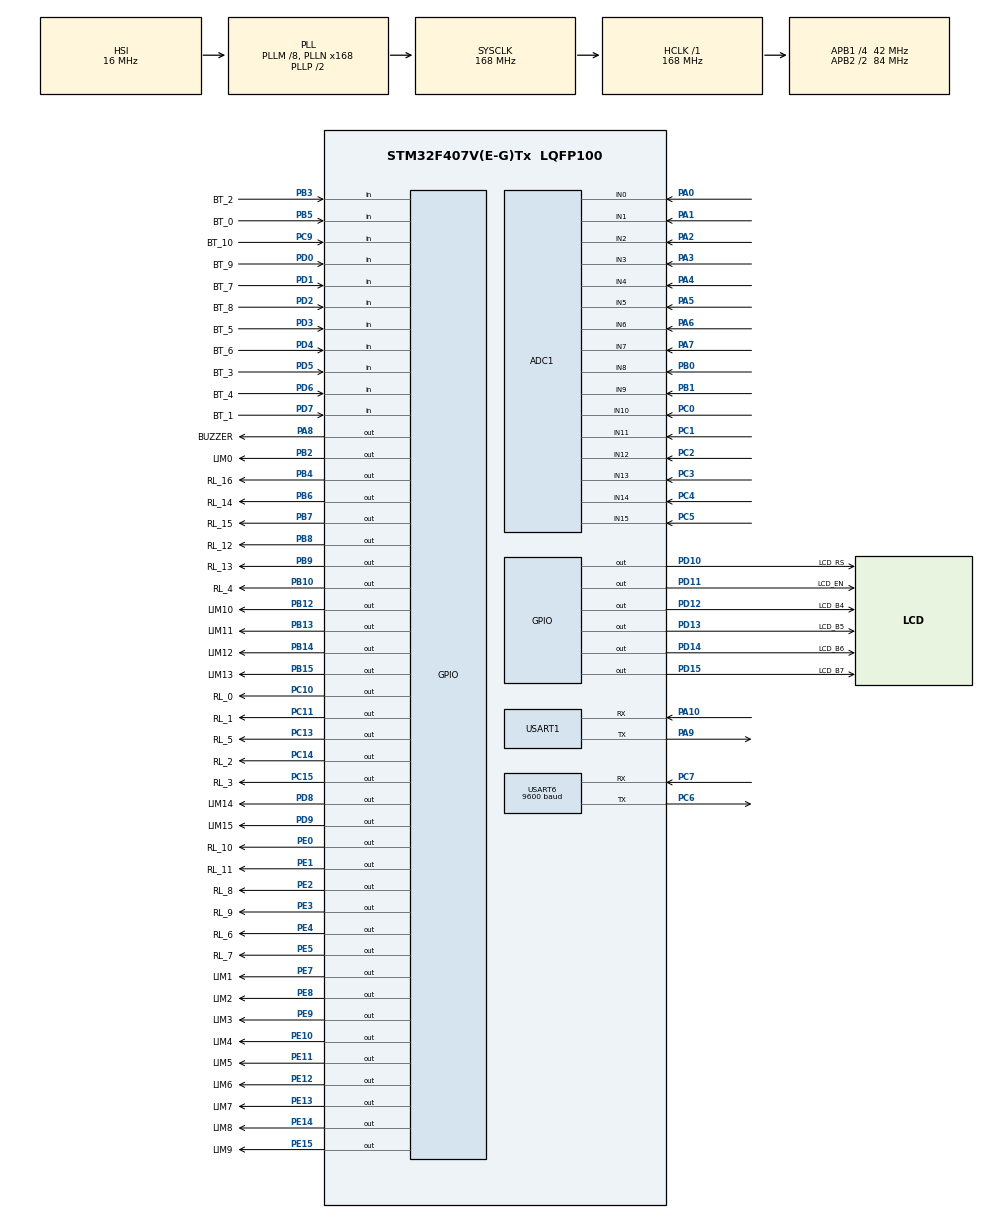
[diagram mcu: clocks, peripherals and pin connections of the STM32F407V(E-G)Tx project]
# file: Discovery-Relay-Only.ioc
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ADC1.Channel-0\#ChannelRegularConversion=ADC_CHANNEL_10
ADC1.Channel-1\#ChannelRegularConversion=ADC_CHANNEL_11
ADC1.Channel-10\#ChannelRegularConversion=ADC_CHANNEL_6
ADC1.Channel-11\#ChannelRegularConversion=ADC_CHANNEL_7
ADC1.Channel-12\#ChannelRegularConversion=ADC_CHANNEL_14
ADC1.Channel-13\#ChannelRegularConversion=ADC_CHANNEL_15
ADC1.Channel-14\#ChannelRegularConversion=ADC_CHANNEL_8
ADC1.Channel-15\#ChannelRegularConversion=ADC_CHANNEL_9
ADC1.Channel-2\#ChannelRegularConversion=ADC_CHANNEL_12
ADC1.Channel-3\#ChannelRegularConversion=ADC_CHANNEL_13
ADC1.Channel-4\#ChannelRegularConversion=ADC_CHANNEL_0
ADC1.Channel-5\#ChannelRegularConversion=ADC_CHANNEL_1
ADC1.Channel-6\#ChannelRegularConversion=ADC_CHANNEL_2
ADC1.Channel-7\#ChannelRegularConversion=ADC_CHANNEL_3
ADC1.Channel-8\#ChannelRegularConversion=ADC_CHANNEL_4
ADC1.Channel-9\#ChannelRegularConversion=ADC_CHANNEL_5
ADC1.ContinuousConvMode=ENABLE
ADC1.DMAContinuousRequests=ENABLE
ADC1.NbrOfConversion=16
ADC1.NbrOfConversionFlag=1
ADC1.Rank-0\#ChannelRegularConversion=1
ADC1.Rank-1\#ChannelRegularConversion=2
ADC1.Rank-10\#ChannelRegularConversion=11
ADC1.Rank-11\#ChannelRegularConversion=12
ADC1.Rank-12\#ChannelRegularConversion=13
ADC1.Rank-13\#ChannelRegularConversion=14
ADC1.Rank-14\#ChannelRegularConversion=15
ADC1.Rank-15\#ChannelRegularConversion=16
ADC1.Rank-2\#ChannelRegularConversion=3
ADC1.Rank-3\#ChannelRegularConversion=4
ADC1.Rank-4\#ChannelRegularConversion=5
ADC1.Rank-5\#ChannelRegularConversion=6
ADC1.Rank-6\#ChannelRegularConversion=7
ADC1.Rank-7\#ChannelRegularConversion=8
ADC1.Rank-8\#ChannelRegularConversion=9
ADC1.Rank-9\#ChannelRegularConversion=10
ADC1.SamplingTime-0\#ChannelRegularConversion=ADC_SAMPLETIME_480CYCLES
ADC1.SamplingTime-1\#ChannelRegularConversion=ADC_SAMPLETIME_480CYCLES
ADC1.SamplingTime-10\#ChannelRegularConversion=ADC_SAMPLETIME_480CYCLES
ADC1.SamplingTime-11\#ChannelRegularConversion=ADC_SAMPLETIME_480CYCLES
ADC1.SamplingTime-12\#ChannelRegularConversion=ADC_SAMPLETIME_480CYCLES
ADC1.SamplingTime-13\#ChannelRegularConversion=ADC_SAMPLETIME_480CYCLES
ADC1.SamplingTime-14\#ChannelRegularConversion=ADC_SAMPLETIME_480CYCLES
ADC1.SamplingTime-15\#ChannelRegularConversion=ADC_SAMPLETIME_480CYCLES
ADC1.SamplingTime-2\#ChannelRegularConversion=ADC_SAMPLETIME_480CYCLES
ADC1.SamplingTime-3\#ChannelRegularConversion=ADC_SAMPLETIME_480CYCLES
ADC1.SamplingTime-4\#ChannelRegularConversion=ADC_SAMPLETIME_480CYCLES
ADC1.SamplingTime-5\#ChannelRegularConversion=ADC_SAMPLETIME_480CYCLES
ADC1.SamplingTime-6\#ChannelRegularConversion=ADC_SAMPLETIME_480CYCLES
ADC1.SamplingTime-7\#ChannelRegularConversion=ADC_SAMPLETIME_480CYCLES
ADC1.SamplingTime-8\#ChannelRegularConversion=ADC_SAMPLETIME_480CYCLES
ADC1.SamplingTime-9\#ChannelRegularConversion=ADC_SAMPLETIME_480CYCLES
ADC1.ScanConvMode=ENABLE
ADC1.master=1
Dma.ADC1.0.Direction=DMA_PERIPH_TO_MEMORY
Dma.ADC1.0.FIFOMode=DMA_FIFOMODE_DISABLE
Dma.ADC1.0.Instance=DMA2_Stream0
Dma.ADC1.0.MemDataAlignment=DMA_MDATAALIGN_WORD
Dma.ADC1.0.MemInc=DMA_MINC_ENABLE
Dma.ADC1.0.Mode=DMA_CIRCULAR
Dma.ADC1.0.PeriphDataAlignment=DMA_PDATAALIGN_WORD
Dma.ADC1.0.PeriphInc=DMA_PINC_DISABLE
Dma.ADC1.0.Priority=DMA_PRIORITY_LOW
Dma.Request0=ADC1
Dma.Request1=USART1_RX
Dma.USART1_RX.1.Direction=DMA_PERIPH_TO_MEMORY
Dma.USART1_RX.1.FIFOMode=DMA_FIFOMODE_DISABLE
Dma.USART1_RX.1.Instance=DMA2_Stream2
Dma.USART1_RX.1.MemDataAlignment=DMA_MDATAALIGN_BYTE
Dma.USART1_RX.1.MemInc=DMA_MINC_ENABLE
Dma.USART1_RX.1.Mode=DMA_NORMAL
Dma.USART1_RX.1.PeriphDataAlignment=DMA_PDATAALIGN_BYTE
Dma.USART1_RX.1.PeriphInc=DMA_PINC_DISABLE
Dma.USART1_RX.1.Priority=DMA_PRIORITY_LOW
Mcu.Family=STM32F4
Mcu.Name=STM32F407V(E-G)Tx
Mcu.Package=LQFP100
NVIC.DMA2_Stream0_IRQn=true\:0\:0\:false\:false\:true\:false\:true\:true
NVIC.DMA2_Stream2_IRQn=true\:0\:0\:false\:false\:true\:false\:true\:true
NVIC.PriorityGroup=NVIC_PRIORITYGROUP_4
NVIC.TIM6_DAC_IRQn=true\:0\:0\:false\:false\:true\:true\:true\:true
NVIC.USART1_IRQn=true\:0\:0\:false\:false\:true\:true\:true\:true
NVIC.USART6_IRQn=true\:0\:0\:false\:false\:true\:true\:true\:true
PA0-WKUP.Signal=ADCx_IN0
PA1.Signal=ADCx_IN1
PA10.Mode=Asynchronous
PA10.Signal=USART1_RX
PA13.Mode=Serial_Wire
PA13.Signal=SYS_JTMS-SWDIO
PA14.Mode=Serial_Wire
PA14.Signal=SYS_JTCK-SWCLK
PA2.Signal=ADCx_IN2
PA3.Signal=ADCx_IN3
PA4.Signal=ADCx_IN4
PA5.Signal=ADCx_IN5
PA6.Signal=ADCx_IN6
PA7.Signal=ADCx_IN7
PA8.GPIO_Label=BUZZER
PA8.Signal=GPIO_Output
PA9.Mode=Asynchronous
PA9.Signal=USART1_TX
PB0.Signal=ADCx_IN8
PB1.Signal=ADCx_IN9
PB10.GPIO_Label=RL_4
PB10.Signal=GPIO_Output
PB12.GPIO_Label=LIM10
PB12.Signal=GPIO_Output
PB13.GPIO_Label=LIM11
PB13.Signal=GPIO_Output
PB14.GPIO_Label=LIM12
PB14.Signal=GPIO_Output
PB15.GPIO_Label=LIM13
PB15.Signal=GPIO_Output
PB2.GPIO_Label=LIM0
PB2.Signal=GPIO_Output
PB3.GPIO_Label=BT_2
PB3.GPIO_PuPd=GPIO_PULLUP
PB3.Signal=GPIO_Input
PB4.GPIO_Label=RL_16
PB4.Signal=GPIO_Output
PB5.GPIO_Label=BT_0
PB5.GPIO_PuPd=GPIO_PULLUP
PB5.Signal=GPIO_Input
PB6.GPIO_Label=RL_14
PB6.Signal=GPIO_Output
PB7.GPIO_Label=RL_15
PB7.Signal=GPIO_Output
PB8.GPIO_Label=RL_12
PB8.Signal=GPIO_Output
PB9.GPIO_Label=RL_13
PB9.Signal=GPIO_Output
PC0.Signal=ADCx_IN10
PC1.Signal=ADCx_IN11
PC10.GPIO_Label=RL_0
PC10.Signal=GPIO_Output
PC11.GPIO_Label=RL_1
PC11.Signal=GPIO_Output
PC13-ANTI_TAMP.GPIO_Label=RL_5
PC13-ANTI_TAMP.Signal=GPIO_Output
PC14-OSC32_IN.GPIO_Label=RL_2
PC14-OSC32_IN.Signal=GPIO_Output
PC15-OSC32_OUT.GPIO_Label=RL_3
PC15-OSC32_OUT.Signal=GPIO_Output
PC2.Signal=ADCx_IN12
PC3.Signal=ADCx_IN13
PC4.Signal=ADCx_IN14
PC5.Signal=ADCx_IN15
PC6.Mode=Asynchronous
PC6.Signal=USART6_TX
PC7.Mode=Asynchronous
PC7.Signal=USART6_RX
PC9.GPIO_Label=BT_10
PC9.GPIO_PuPd=GPIO_PULLUP
PC9.Signal=GPIO_Input
PD0.GPIO_Label=BT_9
PD0.GPIO_PuPd=GPIO_PULLUP
PD0.Signal=GPIO_Input
PD1.GPIO_Label=BT_7
PD1.GPIO_PuPd=GPIO_PULLUP
PD1.Signal=GPIO_Input
PD10.GPIO_Label=LCD_RS
PD10.Signal=GPIO_Output
PD11.GPIO_Label=LCD_EN
PD11.Signal=GPIO_Output
PD12.GPIO_Label=LCD_B4
PD12.Signal=GPIO_Output
PD13.GPIO_Label=LCD_B5
PD13.Signal=GPIO_Output
PD14.GPIO_Label=LCD_B6
PD14.Signal=GPIO_Output
PD15.GPIO_Label=LCD_B7
PD15.Signal=GPIO_Output
PD2.GPIO_Label=BT_8
PD2.GPIO_PuPd=GPIO_PULLUP
PD2.Signal=GPIO_Input
PD3.GPIO_Label=BT_5
PD3.GPIO_PuPd=GPIO_PULLUP
PD3.Signal=GPIO_Input
PD4.GPIO_Label=BT_6
PD4.GPIO_PuPd=GPIO_PULLUP
PD4.Signal=GPIO_Input
PD5.GPIO_Label=BT_3
PD5.GPIO_PuPd=GPIO_PULLUP
PD5.Signal=GPIO_Input
PD6.GPIO_Label=BT_4
PD6.GPIO_PuPd=GPIO_PULLUP
PD6.Signal=GPIO_Input
PD7.GPIO_Label=BT_1
PD7.GPIO_PuPd=GPIO_PULLUP
PD7.Signal=GPIO_Input
PD8.GPIO_Label=LIM14
PD8.Signal=GPIO_Output
PD9.GPIO_Label=LIM15
PD9.Signal=GPIO_Output
PE0.GPIO_Label=RL_10
PE0.Signal=GPIO_Output
PE1.GPIO_Label=RL_11
PE1.Signal=GPIO_Output
PE10.GPIO_Label=LIM4
PE10.Signal=GPIO_Output
PE11.GPIO_Label=LIM5
PE11.Signal=GPIO_Output
PE12.GPIO_Label=LIM6
PE12.Signal=GPIO_Output
PE13.GPIO_Label=LIM7
PE13.Signal=GPIO_Output
PE14.GPIO_Label=LIM8
PE14.Signal=GPIO_Output
PE15.GPIO_Label=LIM9
PE15.Signal=GPIO_Output
PE2.GPIO_Label=RL_8
PE2.Signal=GPIO_Output
PE3.GPIO_Label=RL_9
PE3.Signal=GPIO_Output
PE4.GPIO_Label=RL_6
PE4.Signal=GPIO_Output
PE5.GPIO_Label=RL_7
PE5.Signal=GPIO_Output
PE7.GPIO_Label=LIM1
PE7.Signal=GPIO_Output
PE8.GPIO_Label=LIM2
PE8.Signal=GPIO_Output
PE9.GPIO_Label=LIM3
PE9.Signal=GPIO_Output
PH0-OSC_IN.Mode=HSE-External-Oscillator
PH0-OSC_IN.Signal=RCC_OSC_IN
PH1-OSC_OUT.Mode=HSE-External-Oscillator
PH1-OSC_OUT.Signal=RCC_OSC_OUT
ProjectManager.HeapSize=0x200
ProjectManager.StackSize=0x400
ProjectManager.TargetToolchain=MDK-ARM V5.32
RCC.48MHZClocksFreq_Value=84000000
RCC.AHBFreq_Value=168000000
RCC.APB1CLKDivider=RCC_HCLK_DIV4
RCC.APB1Freq_Value=42000000
RCC.APB1TimFreq_Value=84000000
RCC.APB2CLKDivider=RCC_HCLK_DIV2
RCC.APB2Freq_Value=84000000
RCC.APB2TimFreq_Value=168000000
RCC.CortexFreq_Value=168000000
RCC.HCLKFreq_Value=168000000
RCC.HSE_VALUE=25000000
RCC.HSI_VALUE=16000000
RCC.LSE_VALUE=32768
RCC.PLLM=8
RCC.PLLN=168
RCC.SYSCLKFreq_VALUE=168000000
RCC.SYSCLKSource=RCC_SYSCLKSOURCE_PLLCLK
RCC.VCOOutputFreq_Value=336000000
SH.ADCx_IN0.0=ADC1_IN0,IN0
SH.ADCx_IN1.0=ADC1_IN1,IN1
SH.ADCx_IN10.0=ADC1_IN10,IN10
SH.ADCx_IN11.0=ADC1_IN11,IN11
SH.ADCx_IN12.0=ADC1_IN12,IN12
SH.ADCx_IN13.0=ADC1_IN13,IN13
SH.ADCx_IN14.0=ADC1_IN14,IN14
SH.ADCx_IN15.0=ADC1_IN15,IN15
SH.ADCx_IN2.0=ADC1_IN2,IN2
SH.ADCx_IN3.0=ADC1_IN3,IN3
SH.ADCx_IN4.0=ADC1_IN4,IN4
SH.ADCx_IN5.0=ADC1_IN5,IN5
SH.ADCx_IN6.0=ADC1_IN6,IN6
SH.ADCx_IN7.0=ADC1_IN7,IN7
SH.ADCx_IN8.0=ADC1_IN8,IN8
SH.ADCx_IN9.0=ADC1_IN9,IN9
TIM6.AutoReloadPreload=TIM_AUTORELOAD_PRELOAD_DISABLE
TIM6.Period=999
TIM6.Prescaler=41+1
USART1.VirtualMode=VM_ASYNC
USART6.BaudRate=9600
USART6.VirtualMode=VM_ASYNC
VP_TIM6_VS_ClockSourceINT.Mode=Enable_Timer
board=custom

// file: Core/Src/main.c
/* USER CODE BEGIN Header */
/**
  ******************************************************************************
  * @file           : main.c
  * @brief          : Main program body
  ******************************************************************************
  * @attention
  *
  * Copyright (c) 2022 STMicroelectronics.
  * All rights reserved.
  *
  * This software is licensed under terms that can be found in the LICENSE file
  * in the root directory of this software component.
  * If no LICENSE file comes with this software, it is provided AS-IS.
  *
  ******************************************************************************
  */
/* USER CODE END Header */
#include "main.h"
#include "stdbool.h"
#include "stdio.h"
#include "LCD_Lib.h"
#include "Header.h"
#include "String.h"
#include "DWT_Delay.h"

/* USER CODE BEGIN PD */
#define USART_BUF_SIZE 128
/* USER CODE END PD */

ADC_HandleTypeDef hadc1;
DMA_HandleTypeDef hdma_adc1;

TIM_HandleTypeDef htim6;

UART_HandleTypeDef huart1;
UART_HandleTypeDef huart6;
DMA_HandleTypeDef hdma_usart1_rx;

/* USER CODE BEGIN PV */
uint8_t USART_pBuffer[USART_BUF_SIZE * 2];
uint8_t stringBuffer[USART_BUF_SIZE];
bool USART_status = false;
char bufferr[128];
uint32_t adcBuffer[16];
bool systemSetOK = false;

/*TIMER DATA PACKAGE*/
unsigned char s_data1[8]; //= {1,1,1,1,0,0,0,1};
unsigned char s_data2[8]; //= {0,1,0,0,0,1,1,1};

unsigned char s_dat[16] = {0,1,2,1,1,2,1,1,0,0,0,1,1,2,3,1};

unsigned char data_packet[19];
unsigned char data_length;
uint8_t header = 255;
uint8_t footer = 254;
static uint16_t time_c = 0;
bool tx_busy = 0;
static int MAX_DATA_COUNT = 8;

extern char buffer[25];

/* USER CODE END PV */

void SystemClock_Config(void);
static void MX_GPIO_Init(void);
static void MX_DMA_Init(void);
static void MX_ADC1_Init(void);
static void MX_USART1_UART_Init(void);
static void MX_TIM6_Init(void);
static void MX_USART6_UART_Init(void);

/* USER CODE BEGIN 0 */
void sendDataPacket(void);
/* USER CODE END 0 */

int main(void)
{

  /* MCU Configuration--------------------------------------------------------*/

  /* Reset of all peripherals, Initializes the Flash interface and the Systick. */
  HAL_Init();

  /* Configure the system clock */
  SystemClock_Config();

  /* Initialize all configured peripherals */
  MX_GPIO_Init();
  MX_DMA_Init();
  MX_ADC1_Init();
  MX_USART1_UART_Init();
  MX_TIM6_Init();
  MX_USART6_UART_Init();
  /* USER CODE BEGIN 2 */
	HAL_ADC_Start_DMA(&hadc1, adcBuffer, 16);
//	HAL_UART_Init(&huart1);
//	HAL_UART_Init(&huart6);
//	//HAL_TIM_Base_Start_IT(&htim6);
	HAL_UART_Init(&huart1);
	HAL_UART_Init(&huart6);
	HAL_TIM_Base_Start_IT(&htim6);
	//HAL_UARTEx_ReceiveToIdle_DMA(&huart1, USART_pBuffer, USART_BUF_SIZE);
	//__HAL_DMA_DISABLE_IT(&hdma_usart1_rx, DMA_IT_HT);
	LCD_Init(40,2);
	LCD_CursorSet(0,0);
	LCD_Putsxy(0, 0,"====> MUTANT 2.1B <====");
	LCD_Putsxy(0, 1,"  ==> FIRE ALARM <==");
	DWT_Delayms(1000);
	LCD_Clear();
  /* USER CODE END 2 */

  /* Infinite loop */
  while (1)
  {
    /* USER CODE END WHILE */
		//HAL_Delay(10000);
		//relayOn(0xFF);
//		relayOn(0xFF);
		//limitOn(0xFF);
//		buzzerOn(1000);
//		buzzerOff(1000);
//		checkButton();
		if(systemSetOK == false){
			while(1){
				if(systemSetOK == false){
					systemSetOK =  selectMenu();

					//limitOn(0xFF);
					LCD_Clear();
				}else{
					sprintf(bufferr, "MODE %d || INT %d", selectedSensingMode, valueSetInterval);
					LCD_Putsxy(0,0, "SYSTEM RUNNING");
					LCD_Putsxy(0,1, bufferr);
					//sendDateTime();
					//if(flagRx == true){parsingDataF1();}					//Parsing DATA
					DWT_Delayms(2000);
					LCD_Clear();
					break;
				}
			}
		}else{
		// JALANKAN PROGRAM RUNNING SYSTEM IN HERE
			if(selectedSensingMode == 1){
				LCD_Putsxy(13,0, "MUTANT 2.1B");
				//LCD_Putsxy(10, 1, dateTime);
				//if(flagRx == true){parsingDataF1();}					//Parsing DATA
				modeSingleWire();
				//if(flag_send_data){sendDataPacket();}
				//checkSortAndOpenCircuit();
				//checkSupply();
			}else if(selectedSensingMode == 2){
				LCD_Putsxy(13,0, "MUTANT 2.1B");
				//LCD_Putsxy(10, 1, dateTime);
				//if(flagRx == true){parsingDataF1();}					//Parsing DATA
				modeCrossWire();
				//if(flag_send_data){sendDataPacket();}
				//checkSortAndOpenCircuit();
				//checkSupply();
			}
		}
  }
}

void SystemClock_Config(void)
{
  RCC_OscInitTypeDef RCC_OscInitStruct = {0};
  RCC_ClkInitTypeDef RCC_ClkInitStruct = {0};

  /** Configure the main internal regulator output voltage
  */
  __HAL_RCC_PWR_CLK_ENABLE();
  __HAL_PWR_VOLTAGESCALING_CONFIG(PWR_REGULATOR_VOLTAGE_SCALE1);

  /** Initializes the RCC Oscillators according to the specified parameters
  * in the RCC_OscInitTypeDef structure.
  */
  RCC_OscInitStruct.OscillatorType = RCC_OSCILLATORTYPE_HSI;
  RCC_OscInitStruct.HSIState = RCC_HSI_ON;
  RCC_OscInitStruct.HSICalibrationValue = RCC_HSICALIBRATION_DEFAULT;
  RCC_OscInitStruct.PLL.PLLState = RCC_PLL_ON;
  RCC_OscInitStruct.PLL.PLLSource = RCC_PLLSOURCE_HSI;
  RCC_OscInitStruct.PLL.PLLM = 8;
  RCC_OscInitStruct.PLL.PLLN = 168;
  RCC_OscInitStruct.PLL.PLLP = RCC_PLLP_DIV2;
  RCC_OscInitStruct.PLL.PLLQ = 4;
  if (HAL_RCC_OscConfig(&RCC_OscInitStruct) != HAL_OK)
  {
    Error_Handler();
  }

  /** Initializes the CPU, AHB and APB buses clocks
  */
  RCC_ClkInitStruct.ClockType = RCC_CLOCKTYPE_HCLK|RCC_CLOCKTYPE_SYSCLK
                              |RCC_CLOCKTYPE_PCLK1|RCC_CLOCKTYPE_PCLK2;
  RCC_ClkInitStruct.SYSCLKSource = RCC_SYSCLKSOURCE_PLLCLK;
  RCC_ClkInitStruct.AHBCLKDivider = RCC_SYSCLK_DIV1;
  RCC_ClkInitStruct.APB1CLKDivider = RCC_HCLK_DIV4;
  RCC_ClkInitStruct.APB2CLKDivider = RCC_HCLK_DIV2;

  if (HAL_RCC_ClockConfig(&RCC_ClkInitStruct, FLASH_LATENCY_5) != HAL_OK)
  {
    Error_Handler();
  }
}

static void MX_ADC1_Init(void)
{

  ADC_ChannelConfTypeDef sConfig = {0};

  /** Configure the global features of the ADC (Clock, Resolution, Data Alignment and number of conversion)
  */
  hadc1.Instance = ADC1;
  hadc1.Init.ClockPrescaler = ADC_CLOCK_SYNC_PCLK_DIV4;
  hadc1.Init.Resolution = ADC_RESOLUTION_12B;
  hadc1.Init.ScanConvMode = ENABLE;
  hadc1.Init.ContinuousConvMode = ENABLE;
  hadc1.Init.DiscontinuousConvMode = DISABLE;
  hadc1.Init.ExternalTrigConvEdge = ADC_EXTERNALTRIGCONVEDGE_NONE;
  hadc1.Init.ExternalTrigConv = ADC_SOFTWARE_START;
  hadc1.Init.DataAlign = ADC_DATAALIGN_RIGHT;
  hadc1.Init.NbrOfConversion = 16;
  hadc1.Init.DMAContinuousRequests = ENABLE;
  hadc1.Init.EOCSelection = ADC_EOC_SINGLE_CONV;
  if (HAL_ADC_Init(&hadc1) != HAL_OK)
  {
    Error_Handler();
  }

  /** Configure for the selected ADC regular channel its corresponding rank in the sequencer and its sample time.
  */
  sConfig.Channel = ADC_CHANNEL_10;
  sConfig.Rank = 1;
  sConfig.SamplingTime = ADC_SAMPLETIME_480CYCLES;
  if (HAL_ADC_ConfigChannel(&hadc1, &sConfig) != HAL_OK)
  {
    Error_Handler();
  }

  /** Configure for the selected ADC regular channel its corresponding rank in the sequencer and its sample time.
  */
  sConfig.Channel = ADC_CHANNEL_11;
  sConfig.Rank = 2;
  if (HAL_ADC_ConfigChannel(&hadc1, &sConfig) != HAL_OK)
  {
    Error_Handler();
  }

  /** Configure for the selected ADC regular channel its corresponding rank in the sequencer and its sample time.
  */
  sConfig.Channel = ADC_CHANNEL_12;
  sConfig.Rank = 3;
  if (HAL_ADC_ConfigChannel(&hadc1, &sConfig) != HAL_OK)
  {
    Error_Handler();
  }

  /** Configure for the selected ADC regular channel its corresponding rank in the sequencer and its sample time.
  */
  sConfig.Channel = ADC_CHANNEL_13;
  sConfig.Rank = 4;
  if (HAL_ADC_ConfigChannel(&hadc1, &sConfig) != HAL_OK)
  {
    Error_Handler();
  }

  /** Configure for the selected ADC regular channel its corresponding rank in the sequencer and its sample time.
  */
  sConfig.Channel = ADC_CHANNEL_0;
  sConfig.Rank = 5;
  if (HAL_ADC_ConfigChannel(&hadc1, &sConfig) != HAL_OK)
  {
    Error_Handler();
  }

  /** Configure for the selected ADC regular channel its corresponding rank in the sequencer and its sample time.
  */
  sConfig.Channel = ADC_CHANNEL_1;
  sConfig.Rank = 6;
  if (HAL_ADC_ConfigChannel(&hadc1, &sConfig) != HAL_OK)
  {
    Error_Handler();
  }

  /** Configure for the selected ADC regular channel its corresponding rank in the sequencer and its sample time.
  */
  sConfig.Channel = ADC_CHANNEL_2;
  sConfig.Rank = 7;
  if (HAL_ADC_ConfigChannel(&hadc1, &sConfig) != HAL_OK)
  {
    Error_Handler();
  }

  /** Configure for the selected ADC regular channel its corresponding rank in the sequencer and its sample time.
  */
  sConfig.Channel = ADC_CHANNEL_3;
  sConfig.Rank = 8;
  if (HAL_ADC_ConfigChannel(&hadc1, &sConfig) != HAL_OK)
  {
    Error_Handler();
  }

  /** Configure for the selected ADC regular channel its corresponding rank in the sequencer and its sample time.
  */
  sConfig.Channel = ADC_CHANNEL_4;
  sConfig.Rank = 9;
  if (HAL_ADC_ConfigChannel(&hadc1, &sConfig) != HAL_OK)
  {
    Error_Handler();
  }

  /** Configure for the selected ADC regular channel its corresponding rank in the sequencer and its sample time.
  */
  sConfig.Channel = ADC_CHANNEL_5;
  sConfig.Rank = 10;
  if (HAL_ADC_ConfigChannel(&hadc1, &sConfig) != HAL_OK)
  {
    Error_Handler();
  }

  /** Configure for the selected ADC regular channel its corresponding rank in the sequencer and its sample time.
  */
  sConfig.Channel = ADC_CHANNEL_6;
  sConfig.Rank = 11;
  if (HAL_ADC_ConfigChannel(&hadc1, &sConfig) != HAL_OK)
  {
    Error_Handler();
  }

  /** Configure for the selected ADC regular channel its corresponding rank in the sequencer and its sample time.
  */
  sConfig.Channel = ADC_CHANNEL_7;
  sConfig.Rank = 12;
  if (HAL_ADC_ConfigChannel(&hadc1, &sConfig) != HAL_OK)
  {
    Error_Handler();
  }

  /** Configure for the selected ADC regular channel its corresponding rank in the sequencer and its sample time.
  */
  sConfig.Channel = ADC_CHANNEL_14;
  sConfig.Rank = 13;
  if (HAL_ADC_ConfigChannel(&hadc1, &sConfig) != HAL_OK)
  {
    Error_Handler();
  }

  /** Configure for the selected ADC regular channel its corresponding rank in the sequencer and its sample time.
  */
  sConfig.Channel = ADC_CHANNEL_15;
  sConfig.Rank = 14;
  if (HAL_ADC_ConfigChannel(&hadc1, &sConfig) != HAL_OK)
  {
    Error_Handler();
  }

  /** Configure for the selected ADC regular channel its corresponding rank in the sequencer and its sample time.
  */
  sConfig.Channel = ADC_CHANNEL_8;
  sConfig.Rank = 15;
  if (HAL_ADC_ConfigChannel(&hadc1, &sConfig) != HAL_OK)
  {
    Error_Handler();
  }

  /** Configure for the selected ADC regular channel its corresponding rank in the sequencer and its sample time.
  */
  sConfig.Channel = ADC_CHANNEL_9;
  sConfig.Rank = 16;
  if (HAL_ADC_ConfigChannel(&hadc1, &sConfig) != HAL_OK)
  {
    Error_Handler();
  }

}

static void MX_TIM6_Init(void)
{

  TIM_MasterConfigTypeDef sMasterConfig = {0};

  htim6.Instance = TIM6;
  htim6.Init.Prescaler = 84-1;
  htim6.Init.CounterMode = TIM_COUNTERMODE_UP;
  htim6.Init.Period = 1000-1;
  htim6.Init.AutoReloadPreload = TIM_AUTORELOAD_PRELOAD_DISABLE;
  if (HAL_TIM_Base_Init(&htim6) != HAL_OK)
  {
    Error_Handler();
  }
  sMasterConfig.MasterOutputTrigger = TIM_TRGO_RESET;
  sMasterConfig.MasterSlaveMode = TIM_MASTERSLAVEMODE_DISABLE;
  if (HAL_TIMEx_MasterConfigSynchronization(&htim6, &sMasterConfig) != HAL_OK)
  {
    Error_Handler();
  }

}

static void MX_USART1_UART_Init(void)
{

  huart1.Instance = USART1;
  huart1.Init.BaudRate = 115200;
  huart1.Init.WordLength = UART_WORDLENGTH_8B;
  huart1.Init.StopBits = UART_STOPBITS_1;
  huart1.Init.Parity = UART_PARITY_NONE;
  huart1.Init.Mode = UART_MODE_TX_RX;
  huart1.Init.HwFlowCtl = UART_HWCONTROL_NONE;
  huart1.Init.OverSampling = UART_OVERSAMPLING_16;
  if (HAL_UART_Init(&huart1) != HAL_OK)
  {
    Error_Handler();
  }

}

static void MX_USART6_UART_Init(void)
{

  huart6.Instance = USART6;
  huart6.Init.BaudRate = 9600;
  huart6.Init.WordLength = UART_WORDLENGTH_8B;
  huart6.Init.StopBits = UART_STOPBITS_1;
  huart6.Init.Parity = UART_PARITY_NONE;
  huart6.Init.Mode = UART_MODE_TX_RX;
  huart6.Init.HwFlowCtl = UART_HWCONTROL_NONE;
  huart6.Init.OverSampling = UART_OVERSAMPLING_16;
  if (HAL_UART_Init(&huart6) != HAL_OK)
  {
    Error_Handler();
  }

}

static void MX_DMA_Init(void)
{

  /* DMA controller clock enable */
  __HAL_RCC_DMA2_CLK_ENABLE();

  /* DMA interrupt init */
  /* DMA2_Stream0_IRQn interrupt configuration */
  HAL_NVIC_SetPriority(DMA2_Stream0_IRQn, 0, 0);
  HAL_NVIC_EnableIRQ(DMA2_Stream0_IRQn);
  /* DMA2_Stream2_IRQn interrupt configuration */
  HAL_NVIC_SetPriority(DMA2_Stream2_IRQn, 0, 0);
  HAL_NVIC_EnableIRQ(DMA2_Stream2_IRQn);

}

static void MX_GPIO_Init(void)
{
  GPIO_InitTypeDef GPIO_InitStruct = {0};

  /* GPIO Ports Clock Enable */
  __HAL_RCC_GPIOE_CLK_ENABLE();
  __HAL_RCC_GPIOC_CLK_ENABLE();
  __HAL_RCC_GPIOH_CLK_ENABLE();
  __HAL_RCC_GPIOA_CLK_ENABLE();
  __HAL_RCC_GPIOB_CLK_ENABLE();
  __HAL_RCC_GPIOD_CLK_ENABLE();

  /*Configure GPIO pin Output Level */
  HAL_GPIO_WritePin(GPIOE, RL_8_Pin|RL_9_Pin|RL_6_Pin|RL_7_Pin
                          |LIM1_Pin|LIM2_Pin|LIM3_Pin|LIM4_Pin
                          |LIM5_Pin|LIM6_Pin|LIM7_Pin|LIM8_Pin
                          |LIM9_Pin|RL_10_Pin|RL_11_Pin, GPIO_PIN_RESET);

  /*Configure GPIO pin Output Level */
  HAL_GPIO_WritePin(GPIOC, RL_5_Pin|RL_2_Pin|RL_3_Pin|RL_0_Pin
                          |RL_1_Pin, GPIO_PIN_RESET);

  /*Configure GPIO pin Output Level */
  HAL_GPIO_WritePin(GPIOB, LIM0_Pin|RL_4_Pin|LIM10_Pin|LIM11_Pin
                          |LIM12_Pin|LIM13_Pin|RL_16_Pin|RL_14_Pin
                          |RL_15_Pin|RL_12_Pin|RL_13_Pin, GPIO_PIN_RESET);

  /*Configure GPIO pin Output Level */
  HAL_GPIO_WritePin(GPIOD, LIM14_Pin|LIM15_Pin|LCD_RS_Pin|LCD_EN_Pin
                          |LCD_B4_Pin|LCD_B5_Pin|LCD_B6_Pin|LCD_B7_Pin, GPIO_PIN_RESET);

  /*Configure GPIO pin Output Level */
  HAL_GPIO_WritePin(BUZZER_GPIO_Port, BUZZER_Pin, GPIO_PIN_RESET);

  /*Configure GPIO pins : RL_8_Pin RL_9_Pin RL_6_Pin RL_7_Pin
                           LIM1_Pin LIM2_Pin LIM3_Pin LIM4_Pin
                           LIM5_Pin LIM6_Pin LIM7_Pin LIM8_Pin
                           LIM9_Pin RL_10_Pin RL_11_Pin */
  GPIO_InitStruct.Pin = RL_8_Pin|RL_9_Pin|RL_6_Pin|RL_7_Pin
                          |LIM1_Pin|LIM2_Pin|LIM3_Pin|LIM4_Pin
                          |LIM5_Pin|LIM6_Pin|LIM7_Pin|LIM8_Pin
                          |LIM9_Pin|RL_10_Pin|RL_11_Pin;
  GPIO_InitStruct.Mode = GPIO_MODE_OUTPUT_PP;
  GPIO_InitStruct.Pull = GPIO_NOPULL;
  GPIO_InitStruct.Speed = GPIO_SPEED_FREQ_LOW;
  HAL_GPIO_Init(GPIOE, &GPIO_InitStruct);

  /*Configure GPIO pins : RL_5_Pin RL_2_Pin RL_3_Pin RL_0_Pin
                           RL_1_Pin */
  GPIO_InitStruct.Pin = RL_5_Pin|RL_2_Pin|RL_3_Pin|RL_0_Pin
                          |RL_1_Pin;
  GPIO_InitStruct.Mode = GPIO_MODE_OUTPUT_PP;
  GPIO_InitStruct.Pull = GPIO_NOPULL;
  GPIO_InitStruct.Speed = GPIO_SPEED_FREQ_LOW;
  HAL_GPIO_Init(GPIOC, &GPIO_InitStruct);

  /*Configure GPIO pins : LIM0_Pin RL_4_Pin LIM10_Pin LIM11_Pin
                           LIM12_Pin LIM13_Pin RL_16_Pin RL_14_Pin
                           RL_15_Pin RL_12_Pin RL_13_Pin */
  GPIO_InitStruct.Pin = LIM0_Pin|RL_4_Pin|LIM10_Pin|LIM11_Pin
                          |LIM12_Pin|LIM13_Pin|RL_16_Pin|RL_14_Pin
                          |RL_15_Pin|RL_12_Pin|RL_13_Pin;
  GPIO_InitStruct.Mode = GPIO_MODE_OUTPUT_PP;
  GPIO_InitStruct.Pull = GPIO_NOPULL;
  GPIO_InitStruct.Speed = GPIO_SPEED_FREQ_LOW;
  HAL_GPIO_Init(GPIOB, &GPIO_InitStruct);

  /*Configure GPIO pins : LIM14_Pin LIM15_Pin LCD_RS_Pin LCD_EN_Pin
                           LCD_B4_Pin LCD_B5_Pin LCD_B6_Pin LCD_B7_Pin */
  GPIO_InitStruct.Pin = LIM14_Pin|LIM15_Pin|LCD_RS_Pin|LCD_EN_Pin
                          |LCD_B4_Pin|LCD_B5_Pin|LCD_B6_Pin|LCD_B7_Pin;
  GPIO_InitStruct.Mode = GPIO_MODE_OUTPUT_PP;
  GPIO_InitStruct.Pull = GPIO_NOPULL;
  GPIO_InitStruct.Speed = GPIO_SPEED_FREQ_LOW;
  HAL_GPIO_Init(GPIOD, &GPIO_InitStruct);

  /*Configure GPIO pin : BT_10_Pin */
  GPIO_InitStruct.Pin = BT_10_Pin;
  GPIO_InitStruct.Mode = GPIO_MODE_INPUT;
  GPIO_InitStruct.Pull = GPIO_PULLUP;
  HAL_GPIO_Init(BT_10_GPIO_Port, &GPIO_InitStruct);

  /*Configure GPIO pin : BUZZER_Pin */
  GPIO_InitStruct.Pin = BUZZER_Pin;
  GPIO_InitStruct.Mode = GPIO_MODE_OUTPUT_PP;
  GPIO_InitStruct.Pull = GPIO_NOPULL;
  GPIO_InitStruct.Speed = GPIO_SPEED_FREQ_LOW;
  HAL_GPIO_Init(BUZZER_GPIO_Port, &GPIO_InitStruct);

  /*Configure GPIO pins : BT_9_Pin BT_7_Pin BT_8_Pin BT_5_Pin
                           BT_6_Pin BT_3_Pin BT_4_Pin BT_1_Pin */
  GPIO_InitStruct.Pin = BT_9_Pin|BT_7_Pin|BT_8_Pin|BT_5_Pin
                          |BT_6_Pin|BT_3_Pin|BT_4_Pin|BT_1_Pin;
  GPIO_InitStruct.Mode = GPIO_MODE_INPUT;
  GPIO_InitStruct.Pull = GPIO_PULLUP;
  HAL_GPIO_Init(GPIOD, &GPIO_InitStruct);

  /*Configure GPIO pins : BT_2_Pin BT_0_Pin */
  GPIO_InitStruct.Pin = BT_2_Pin|BT_0_Pin;
  GPIO_InitStruct.Mode = GPIO_MODE_INPUT;
  GPIO_InitStruct.Pull = GPIO_PULLUP;
  HAL_GPIO_Init(GPIOB, &GPIO_InitStruct);

}

/* USER CODE BEGIN 4 */
//void HAL_UARTEx_RxEventCallback(UART_HandleTypeDef *huart, uint16_t Size)
//{
//	if(huart->Instance == USART1){
//		memcpy(stringBuffer, USART_pBuffer, Size);
//		memcpy(tx, stringBuffer, Size);
//		flagRx = true;		// FLAG

//		HAL_UARTEx_ReceiveToIdle_DMA(&huart1, USART_pBuffer, USART_BUF_SIZE);
//		__HAL_DMA_DISABLE_IT(&hdma_usart1_rx, DMA_IT_HT);
//	}
//}
//void get_packet(){
//	data_packet[0] = header;
//	data_packet[1] = selectedSensingMode;
//	memcpy(&data_packet[2], s_dat, 16);
//	data_packet[18] = footer;
//	data_length = sizeof(data_packet);
//}

void HAL_TIM_PeriodElapsedCallback(TIM_HandleTypeDef *htim) {
    if (htim->Instance == TIM6) {
        time_c++;

        if (time_c > 6000) {  // Misal 1 detik
            time_c = 0;
					if(sensor_ready){
						sensor_ready = 0;
						// Siapkan paket data
            data_packet[0] = header;
            data_packet[1] = selectedSensingMode;
            memcpy(&data_packet[2], dataSeg, 16); // Copy s_data1 ke data_packet
            data_packet[18] = footer;

            data_length = sizeof(data_packet);

						HAL_UART_Transmit(&huart6, (uint8_t*)data_packet, data_length, 1000);

            // Kirim data jika UART tidak sibuk
//            if (tx_busy == 0) {
//                tx_busy = 1;
//                //HAL_UART_Transmit_IT(&huart1, (uint8_t*)data_packet, data_length);
//								//HAL_UART_Transmit_IT(&huart6, (uint8_t*)data_packet, data_length);
//								HAL_UART_Transmit(&huart6, (uint8_t*)data_packet, data_length, 1000);
//            }
						}
        }
    }
}

void sendDataPacket(void) {
    // Siapkan paket data
    data_packet[0] = header;
    data_packet[1] = selectedSensingMode; //, jika mau fleksibel bisa dijadikan parameter
    memcpy(&data_packet[2], s_dat, 16); // Copy data sensor
    data_packet[18] = footer;

    data_length = sizeof(data_packet);

    // Kirim data jika UART tidak sibuk
    if (tx_busy == 0) {
        tx_busy = 1;
        HAL_UART_Transmit_IT(&huart1, (uint8_t*)data_packet, data_length);
        HAL_UART_Transmit_IT(&huart6, (uint8_t*)data_packet, data_length);
    }
}

//void HAL_UART_TxCpltCallback(UART_HandleTypeDef *huart) {
//    if (huart->Instance == USART1) {
//        tx_busy = 0;
//    }
//}
/* USER CODE END 4 */

void Error_Handler(void)
{
  __disable_irq();
  while (1)
  {
  }
}
